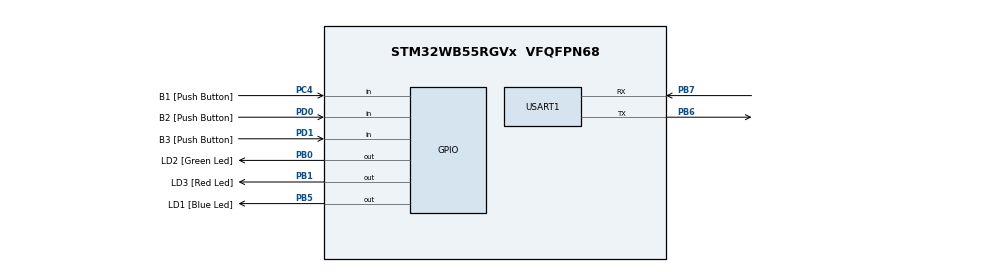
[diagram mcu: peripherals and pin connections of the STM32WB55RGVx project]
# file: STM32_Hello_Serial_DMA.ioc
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Dma.Request0=USART1_TX
Dma.USART1_TX.0.Direction=DMA_MEMORY_TO_PERIPH
Dma.USART1_TX.0.EventEnable=DISABLE
Dma.USART1_TX.0.Instance=DMA1_Channel1
Dma.USART1_TX.0.MemDataAlignment=DMA_MDATAALIGN_BYTE
Dma.USART1_TX.0.MemInc=DMA_MINC_ENABLE
Dma.USART1_TX.0.Mode=DMA_NORMAL
Dma.USART1_TX.0.PeriphDataAlignment=DMA_PDATAALIGN_BYTE
Dma.USART1_TX.0.PeriphInc=DMA_PINC_DISABLE
Dma.USART1_TX.0.Polarity=HAL_DMAMUX_REQ_GEN_RISING
Dma.USART1_TX.0.Priority=DMA_PRIORITY_LOW
Dma.USART1_TX.0.RequestNumber=1
Dma.USART1_TX.0.SignalID=NONE
Dma.USART1_TX.0.SyncEnable=DISABLE
Dma.USART1_TX.0.SyncPolarity=HAL_DMAMUX_SYNC_NO_EVENT
Dma.USART1_TX.0.SyncRequestNumber=1
Dma.USART1_TX.0.SyncSignalID=NONE
Mcu.Family=STM32WB
Mcu.Name=STM32WB55RGVx
Mcu.Package=VFQFPN68
NVIC.DMA1_Channel1_IRQn=true\:0\:0\:false\:false\:true\:false\:true
NVIC.PriorityGroup=NVIC_PRIORITYGROUP_4
NVIC.USART1_IRQn=true\:0\:0\:false\:false\:true\:true\:true
OSC_IN.Mode=HSE-External-Oscillator
OSC_IN.Signal=RCC_OSC_IN
OSC_OUT.Mode=HSE-External-Oscillator
OSC_OUT.Signal=RCC_OSC_OUT
PA11.Signal=USB_DM
PA12.Signal=USB_DP
PA13.GPIO_Label=JTMS
PA13.Signal=SYS_JTMS-SWDIO
PA14.GPIO_Label=JTCK
PA14.Signal=SYS_JTCK-SWCLK
PB0.GPIO_Label=LD2 [Green Led]
PB0.Signal=GPIO_Output
PB1.GPIO_Label=LD3 [Red Led]
PB1.Signal=GPIO_Output
PB3.GPIO_Label=JTDO
PB3.Signal=SYS_JTDO-SWO
PB5.GPIO_Label=LD1 [Blue Led]
PB5.Signal=GPIO_Output
PB6.Mode=Asynchronous
PB6.Signal=USART1_TX
PB7.Mode=Asynchronous
PB7.Signal=USART1_RX
PC13.Signal=SYS_WKUP2
PC14-OSC32_IN.Signal=RCC_OSC32_IN
PC15-OSC32_OUT.Signal=RCC_OSC32_OUT
PC4.GPIO_Label=B1 [Push Button]
PC4.Signal=GPIO_Input
PD0.GPIO_Label=B2 [Push Button]
PD0.Signal=GPIO_Input
PD1.GPIO_Label=B3 [Push Button]
PD1.Signal=GPIO_Input
ProjectManager.HeapSize=0x200
ProjectManager.StackSize=0x400
ProjectManager.TargetToolchain=Makefile
RCC.ADCFreq_Value=128000000
RCC.AHBFreq_Value=32000000
RCC.APB1Freq_Value=32000000
RCC.APB1TimFreq_Value=32000000
RCC.APB2Freq_Value=32000000
RCC.APB2TimFreq_Value=32000000
RCC.APB3Freq_Value=16000000
RCC.CortexFreq_Value=32000000
RCC.HCLKFreq_Value=32000000
RCC.HSE_VALUE=32000000
RCC.HSI48_VALUE=48000000
RCC.HSI_VALUE=16000000
RCC.LSE_VALUE=32768
RCC.MSIClockRange=RCC_MSIRANGE_10
RCC.SMPSCLockSelectionVirtual=RCC_SMPSCLKSOURCE_HSI
RCC.SYSCLKFreq_VALUE=32000000
RCC.USBFreq_Value=128000000
RCC.VCOOutputFreq_Value=256000000
USART1.VirtualMode-Asynchronous=VM_ASYNC
USART1.WordLength=WORDLENGTH_8B
board=P-NUCLEO-WB55-Nucleo

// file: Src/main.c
/* USER CODE BEGIN Header */
/**
  ******************************************************************************
  * @file           : main.c
  * @brief          : Main program body
  ******************************************************************************
  * @attention
  *
  * <h2><center>&copy; Copyright (c) 2019 STMicroelectronics.
  * All rights reserved.</center></h2>
  *
  * This software component is licensed by ST under BSD 3-Clause license,
  * the "License"; You may not use this file except in compliance with the
  * License. You may obtain a copy of the License at:
  *                        opensource.org/licenses/BSD-3-Clause
  *
  ******************************************************************************
  */
/* USER CODE END Header */

#include "main.h"

UART_HandleTypeDef huart1;
DMA_HandleTypeDef hdma_usart1_tx;

/* USER CODE BEGIN PV */
float pi = 3.14159265;
/* USER CODE END PV */

void SystemClock_Config(void);
static void MX_GPIO_Init(void);
static void MX_DMA_Init(void);
static void MX_USART1_UART_Init(void);

int main(void)
{

  /* MCU Configuration--------------------------------------------------------*/

  /* Reset of all peripherals, Initializes the Flash interface and the Systick. */
  HAL_Init();

  /* Configure the system clock */
  SystemClock_Config();

  /* Initialize all configured peripherals */
  MX_GPIO_Init();
  MX_DMA_Init();
  MX_USART1_UART_Init();

  /* Infinite loop */
  /* USER CODE BEGIN WHILE */

  while (1)
  {
    printf("\n\r Pi is %f", pi);
    HAL_Delay(1000);
    /* USER CODE END WHILE */

  }
}

void SystemClock_Config(void)
{
  RCC_OscInitTypeDef RCC_OscInitStruct = {0};
  RCC_ClkInitTypeDef RCC_ClkInitStruct = {0};
  RCC_PeriphCLKInitTypeDef PeriphClkInitStruct = {0};

  /** Configure the main internal regulator output voltage
  */
  __HAL_PWR_VOLTAGESCALING_CONFIG(PWR_REGULATOR_VOLTAGE_SCALE1);
  /** Initializes the CPU, AHB and APB busses clocks
  */
  RCC_OscInitStruct.OscillatorType = RCC_OSCILLATORTYPE_HSI|RCC_OSCILLATORTYPE_HSE
                              |RCC_OSCILLATORTYPE_MSI;
  RCC_OscInitStruct.HSEState = RCC_HSE_ON;
  RCC_OscInitStruct.HSIState = RCC_HSI_ON;
  RCC_OscInitStruct.MSIState = RCC_MSI_ON;
  RCC_OscInitStruct.HSICalibrationValue = RCC_HSICALIBRATION_DEFAULT;
  RCC_OscInitStruct.MSICalibrationValue = RCC_MSICALIBRATION_DEFAULT;
  RCC_OscInitStruct.MSIClockRange = RCC_MSIRANGE_10;
  RCC_OscInitStruct.PLL.PLLState = RCC_PLL_NONE;
  if (HAL_RCC_OscConfig(&RCC_OscInitStruct) != HAL_OK)
  {
    Error_Handler();
  }
  /** Configure the SYSCLKSource, HCLK, PCLK1 and PCLK2 clocks dividers
  */
  RCC_ClkInitStruct.ClockType = RCC_CLOCKTYPE_HCLK4|RCC_CLOCKTYPE_HCLK2
                              |RCC_CLOCKTYPE_HCLK|RCC_CLOCKTYPE_SYSCLK
                              |RCC_CLOCKTYPE_PCLK1|RCC_CLOCKTYPE_PCLK2;
  RCC_ClkInitStruct.SYSCLKSource = RCC_SYSCLKSOURCE_MSI;
  RCC_ClkInitStruct.AHBCLKDivider = RCC_SYSCLK_DIV1;
  RCC_ClkInitStruct.APB1CLKDivider = RCC_HCLK_DIV1;
  RCC_ClkInitStruct.APB2CLKDivider = RCC_HCLK_DIV1;
  RCC_ClkInitStruct.AHBCLK2Divider = RCC_SYSCLK_DIV1;
  RCC_ClkInitStruct.AHBCLK4Divider = RCC_SYSCLK_DIV1;

  if (HAL_RCC_ClockConfig(&RCC_ClkInitStruct, FLASH_LATENCY_1) != HAL_OK)
  {
    Error_Handler();
  }
  /** Initializes the peripherals clocks
  */
  PeriphClkInitStruct.PeriphClockSelection = RCC_PERIPHCLK_SMPS|RCC_PERIPHCLK_USART1;
  PeriphClkInitStruct.Usart1ClockSelection = RCC_USART1CLKSOURCE_PCLK2;
  PeriphClkInitStruct.SmpsClockSelection = RCC_SMPSCLKSOURCE_HSI;
  PeriphClkInitStruct.SmpsDivSelection = RCC_SMPSCLKDIV_RANGE1;

  if (HAL_RCCEx_PeriphCLKConfig(&PeriphClkInitStruct) != HAL_OK)
  {
    Error_Handler();
  }
}

static void MX_USART1_UART_Init(void)
{

  huart1.Instance = USART1;
  huart1.Init.BaudRate = 115200;
  huart1.Init.WordLength = UART_WORDLENGTH_8B;
  huart1.Init.StopBits = UART_STOPBITS_1;
  huart1.Init.Parity = UART_PARITY_NONE;
  huart1.Init.Mode = UART_MODE_TX_RX;
  huart1.Init.HwFlowCtl = UART_HWCONTROL_NONE;
  huart1.Init.OverSampling = UART_OVERSAMPLING_16;
  huart1.Init.OneBitSampling = UART_ONE_BIT_SAMPLE_DISABLE;
  huart1.Init.ClockPrescaler = UART_PRESCALER_DIV1;
  huart1.AdvancedInit.AdvFeatureInit = UART_ADVFEATURE_NO_INIT;
  if (HAL_UART_Init(&huart1) != HAL_OK)
  {
    Error_Handler();
  }
  if (HAL_UARTEx_SetTxFifoThreshold(&huart1, UART_TXFIFO_THRESHOLD_1_8) != HAL_OK)
  {
    Error_Handler();
  }
  if (HAL_UARTEx_SetRxFifoThreshold(&huart1, UART_RXFIFO_THRESHOLD_1_8) != HAL_OK)
  {
    Error_Handler();
  }
  if (HAL_UARTEx_DisableFifoMode(&huart1) != HAL_OK)
  {
    Error_Handler();
  }

}

static void MX_DMA_Init(void)
{

  /* DMA controller clock enable */
  __HAL_RCC_DMAMUX1_CLK_ENABLE();
  __HAL_RCC_DMA1_CLK_ENABLE();

  /* DMA interrupt init */
  /* DMA1_Channel1_IRQn interrupt configuration */
  HAL_NVIC_SetPriority(DMA1_Channel1_IRQn, 0, 0);
  HAL_NVIC_EnableIRQ(DMA1_Channel1_IRQn);

}

static void MX_GPIO_Init(void)
{
  GPIO_InitTypeDef GPIO_InitStruct = {0};

  /* GPIO Ports Clock Enable */
  __HAL_RCC_GPIOC_CLK_ENABLE();
  __HAL_RCC_GPIOB_CLK_ENABLE();
  __HAL_RCC_GPIOA_CLK_ENABLE();
  __HAL_RCC_GPIOD_CLK_ENABLE();

  /*Configure GPIO pin Output Level */
  HAL_GPIO_WritePin(GPIOB, LD2_Pin|LD3_Pin|LD1_Pin, GPIO_PIN_RESET);

  /*Configure GPIO pin : B1_Pin */
  GPIO_InitStruct.Pin = B1_Pin;
  GPIO_InitStruct.Mode = GPIO_MODE_INPUT;
  GPIO_InitStruct.Pull = GPIO_NOPULL;
  HAL_GPIO_Init(B1_GPIO_Port, &GPIO_InitStruct);

  /*Configure GPIO pins : LD2_Pin LD3_Pin LD1_Pin */
  GPIO_InitStruct.Pin = LD2_Pin|LD3_Pin|LD1_Pin;
  GPIO_InitStruct.Mode = GPIO_MODE_OUTPUT_PP;
  GPIO_InitStruct.Pull = GPIO_NOPULL;
  GPIO_InitStruct.Speed = GPIO_SPEED_FREQ_LOW;
  HAL_GPIO_Init(GPIOB, &GPIO_InitStruct);

  /*Configure GPIO pins : PA11 PA12 */
  GPIO_InitStruct.Pin = GPIO_PIN_11|GPIO_PIN_12;
  GPIO_InitStruct.Mode = GPIO_MODE_AF_PP;
  GPIO_InitStruct.Pull = GPIO_NOPULL;
  GPIO_InitStruct.Speed = GPIO_SPEED_FREQ_LOW;
  GPIO_InitStruct.Alternate = GPIO_AF10_USB;
  HAL_GPIO_Init(GPIOA, &GPIO_InitStruct);

  /*Configure GPIO pins : B2_Pin B3_Pin */
  GPIO_InitStruct.Pin = B2_Pin|B3_Pin;
  GPIO_InitStruct.Mode = GPIO_MODE_INPUT;
  GPIO_InitStruct.Pull = GPIO_NOPULL;
  HAL_GPIO_Init(GPIOD, &GPIO_InitStruct);

}

/* USER CODE BEGIN 4 */
void HAL_UART_TxCpltCallback(UART_HandleTypeDef * huart)
{
    HAL_GPIO_TogglePin(LD1_GPIO_Port, LD1_Pin);
    HAL_GPIO_WritePin(LD2_GPIO_Port, LD2_Pin, GPIO_PIN_RESET);
}

void HAL_UART_ErrorCallback(UART_HandleTypeDef * huart)
{
    HAL_GPIO_WritePin(LD2_GPIO_Port, LD2_Pin, GPIO_PIN_SET);
}

/* USER CODE END 4 */

void Error_Handler(void)
{
  /* USER CODE BEGIN Error_Handler_Debug */
  /* User can add his own implementation to report the HAL error return state */
  HAL_GPIO_TogglePin(LD1_GPIO_Port, LD1_Pin);
  HAL_Delay(250);
  HAL_GPIO_TogglePin(LD2_GPIO_Port, LD2_Pin);
  HAL_Delay(250);
  HAL_GPIO_TogglePin(LD3_GPIO_Port, LD3_Pin);
  HAL_Delay(250);
  /* USER CODE END Error_Handler_Debug */
}

/************************ (C) COPYRIGHT STMicroelectronics *****END OF FILE****/
